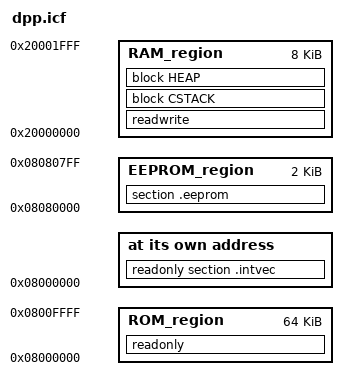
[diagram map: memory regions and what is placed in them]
/*###ICF### Section handled by ICF editor, don't touch! ****/
/*-Editor annotation file-*/
/* IcfEditorFile="$TOOLKIT_DIR$\config\ide\IcfEditor\cortex_v1_0.xml" */
/*-Specials-*/
define symbol __ICFEDIT_intvec_start__ = 0x08000000;
/*-Memory Regions-*/
define symbol __ICFEDIT_region_ROM_start__ = 0x08000000;
define symbol __ICFEDIT_region_ROM_end__   = 0x0800FFFF;
define symbol __ICFEDIT_region_RAM_start__ = 0x20000000;
define symbol __ICFEDIT_region_RAM_end__   = 0x20001FFF;
/*-Sizes-*/
define symbol __ICFEDIT_size_cstack__ = 1024;
define symbol __ICFEDIT_size_heap__   = 0;
/**** End of ICF editor section. ###ICF###*/

define memory mem with size = 4G;
define region ROM_region   = mem:[from __ICFEDIT_region_ROM_start__   to __ICFEDIT_region_ROM_end__];
define region RAM_region   = mem:[from __ICFEDIT_region_RAM_start__   to __ICFEDIT_region_RAM_end__];

define block CSTACK    with alignment = 8, size = __ICFEDIT_size_cstack__   { };
define block HEAP      with alignment = 8, size = __ICFEDIT_size_heap__     { };

initialize by copy { readwrite };
do not initialize  { section .noinit };

place at address mem:__ICFEDIT_intvec_start__ { readonly section .intvec };

place in ROM_region   { readonly };
place in RAM_region   { readwrite,
                        block CSTACK, block HEAP };

define symbol __region_EEPROM_start__ = 0x08080000;
define symbol __region_EEPROM_end__   = 0x080807FF;
define region EEPROM_region = mem:[from __region_EEPROM_start__   to __region_EEPROM_end__];

place in EEPROM_region  { section .eeprom };
                        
